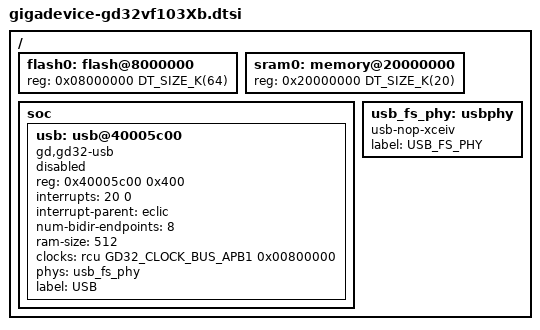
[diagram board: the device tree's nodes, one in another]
/*
 * Copyright (c) 2018 Linaro Limited
 *
 * SPDX-License-Identifier: Apache-2.0
 */

#include <mem.h>
#include <gigadevice-gd32vf1.dtsi>

/ {
	flash0: flash@8000000 {
		reg = <0x08000000 DT_SIZE_K(64)>;
	};

	sram0: memory@20000000 {
		reg = <0x20000000 DT_SIZE_K(20)>;
	};

	soc {
		usb: usb@40005c00 {
			compatible = "gd,gd32-usb";
			reg = <0x40005c00 0x400>;
			interrupts = <20 0>;
			interrupt-parent = <&eclic>;
			interrupt-names = "usb";
			num-bidir-endpoints = <8>;
			ram-size = <512>;
			status = "disabled";
			clocks = <&rcu GD32_CLOCK_BUS_APB1 0x00800000>;
			phys = <&usb_fs_phy>;
			label= "USB";
		};

	};

	usb_fs_phy: usbphy {
		compatible = "usb-nop-xceiv";
		#phy-cells = <0>;
		label = "USB_FS_PHY";
	};
};
